# LargeDummyDevice register map
File version: 1.0
Registers are 32-bit, read-write, no defined reset value unless marked. A register's access mark holds for its fields unless they carry their own. Offsets are from the block's base; [hi:lo] are bit positions.

## PERIPHERAL_80
Base 0x4004F000
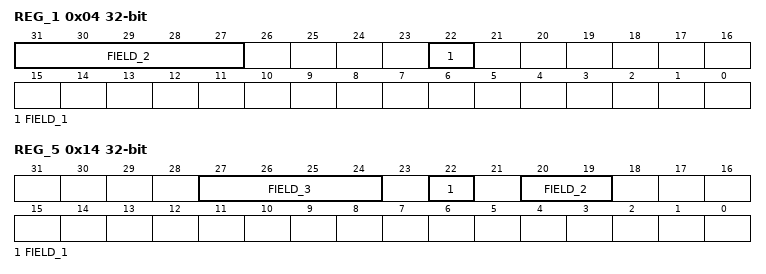
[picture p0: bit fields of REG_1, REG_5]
0x04 REG_1 — Register 1
  [31:27] FIELD_2, [22] FIELD_1
0x08 REG_2 — Register 2
  [28:25] FIELD_6, [24:21] FIELD_1, [22:20] FIELD_17, [18] FIELD_19, [16:14] FIELD_10, [11] FIELD_3, [14:10] FIELD_13, [10:9] FIELD_5, [10:9] FIELD_9, [12:9] FIELD_14, [9] FIELD_16, [6] FIELD_7, [7:5] FIELD_18, [4] FIELD_4, [5:4] FIELD_8, [6:4] FIELD_15, [5:2] FIELD_2, [5:1] FIELD_12, [4:0] FIELD_11
0x0C REG_3 — Register 3
  [24:20] FIELD_4, [23:20] FIELD_6, [17:15] FIELD_5, [8:7] FIELD_1, [8:6] FIELD_2, [1] FIELD_3
0x10 REG_4 — Register 4
  [32:28] FIELD_9, [25] FIELD_10, [25:21] FIELD_4, [18:16] FIELD_3, [14:13] FIELD_5, [16:12] FIELD_2, [12:10] FIELD_6, [10:7] FIELD_1, [6:5] FIELD_8, [5:1] FIELD_7
0x14 REG_5 — Register 5
  [27:24] FIELD_3, [22] FIELD_1, [20:19] FIELD_2
0x18 REG_6 — Register 6
  [13:12] FIELD_3, [2] FIELD_2, [4:0] FIELD_1
0x1C REG_7 — Register 7
  [35:31] FIELD_29, [34:30] FIELD_4, [31:29] FIELD_15, [29] FIELD_30, [32:29] FIELD_31, [30:28] FIELD_17, [27] FIELD_13, [29:27] FIELD_20, [25] FIELD_12, [26:23] FIELD_10, [25:23] FIELD_19, [23] FIELD_23, [22:21] FIELD_24, [22:18] FIELD_28, [16:14] FIELD_7, [17:14] FIELD_8, [14:13] FIELD_1, [13] FIELD_5, [14:12] FIELD_22, [13:11] FIELD_6, [14:10] FIELD_16, [12:8] FIELD_3, [8] FIELD_14, [10:7] FIELD_26, [8:7] FIELD_27, [6:5] FIELD_9, [7:5] FIELD_32, [6:4] FIELD_18, [4:2] FIELD_2, [2:1] FIELD_21, [2:0] FIELD_11, [2:0] FIELD_25
0x20 REG_8 — Register 8
  [28] FIELD_8, [29:27] FIELD_10, [23:22] FIELD_7, [18:14] FIELD_3, [18:14] FIELD_5, [10:7] FIELD_4, [8:7] FIELD_6, [9:5] FIELD_1, [5] FIELD_2, [7:5] FIELD_9, [4:2] FIELD_11
0x24 REG_9 — Register 9
  [31] FIELD_10, [32:31] FIELD_12, [30:29] FIELD_18, [31:27] FIELD_15, [28:27] FIELD_23, [26] FIELD_9, [24] FIELD_1, [26:24] FIELD_14, [22] FIELD_3, [21:20] FIELD_13, [23:20] FIELD_20, [22:19] FIELD_11, [21:18] FIELD_17, [17] FIELD_7, [19:16] FIELD_2, [16:14] FIELD_22, [13:12] FIELD_5, [11] FIELD_21, [10:9] FIELD_6, [6:5] FIELD_16, [5:2] FIELD_8, [4:2] FIELD_19, [5:1] FIELD_4
0x28 REG_10 — Register 10
  [33:30] FIELD_3, [29:28] FIELD_7, [24:22] FIELD_5, [12:11] FIELD_6, [12:8] FIELD_2, [11:7] FIELD_4, [7:4] FIELD_1
0x2C REG_11 — Register 11
  [32:31] FIELD_6, [31] FIELD_24, [32:30] FIELD_10, [29] FIELD_15, [31:27] FIELD_2, [26] FIELD_9, [27:25] FIELD_26, [26:23] FIELD_17, [22] FIELD_3, [24:22] FIELD_28, [23:21] FIELD_5, [24:21] FIELD_16, [23:21] FIELD_21, [17] FIELD_7, [18:15] FIELD_1, [15:14] FIELD_11, [14] FIELD_12, [18:14] FIELD_20, [14:13] FIELD_18, [11] FIELD_8, [8] FIELD_4, [11:8] FIELD_14, [11:7] FIELD_19, [7:6] FIELD_23, [9:5] FIELD_25, [3:2] FIELD_22, [4:2] FIELD_27, [1] FIELD_13
0x30 REG_12 — Register 12
  [33:31] FIELD_8, [29:28] FIELD_4, [26:22] FIELD_1, [23:21] FIELD_13, [20] FIELD_6, [18:15] FIELD_10, [15:13] FIELD_7, [11] FIELD_9, [13:9] FIELD_3, [11:8] FIELD_5, [8:7] FIELD_11, [7:6] FIELD_12, [7:4] FIELD_2, [5:1] FIELD_14
0x34 REG_13 — Register 13
  [31:30] FIELD_9, [32:30] FIELD_11, [30:28] FIELD_14, [31:27] FIELD_13, [29:25] FIELD_15, [23] FIELD_17, [27:23] FIELD_19, [24:22] FIELD_16, [22:20] FIELD_8, [20:19] FIELD_10, [20:18] FIELD_5, [19:18] FIELD_7, [20:17] FIELD_21, [17:16] FIELD_20, [15:13] FIELD_2, [10] FIELD_1, [13:10] FIELD_3, [11:10] FIELD_23, [8] FIELD_22, [6:3] FIELD_4, [4:3] FIELD_18, [1] FIELD_12, [4:0] FIELD_6
0x38 REG_14 — Register 14
  [31:30] FIELD_3, [33:30] FIELD_13, [26] FIELD_7, [22:21] FIELD_11, [20:17] FIELD_4, [19:15] FIELD_6, [16:14] FIELD_2, [14] FIELD_5, [14] FIELD_9, [10:8] FIELD_12, [11:7] FIELD_10, [6:5] FIELD_8, [6:2] FIELD_1
0x3C REG_15 — Register 15
  [34:30] FIELD_2, [32:30] FIELD_3, [33:30] FIELD_8, [30:28] FIELD_1, [27] FIELD_11, [27] FIELD_17, [27:25] FIELD_15, [26:24] FIELD_13, [19:18] FIELD_10, [11] FIELD_6, [8:6] FIELD_16, [9:5] FIELD_4, [8:5] FIELD_7, [8:5] FIELD_9, [5:4] FIELD_5, [3:1] FIELD_14, [2:0] FIELD_12
0x40 REG_16 — Register 16
  [29:27] FIELD_8, [31:27] FIELD_9, [28:25] FIELD_6, [22:18] FIELD_4, [19:16] FIELD_10, [15:13] FIELD_1, [16:13] FIELD_2, [15:13] FIELD_5, [5] FIELD_7, [7:4] FIELD_11, [4:3] FIELD_3
0x44 REG_17 — Register 17
  [34:31] FIELD_11, [32:29] FIELD_13, [31:28] FIELD_14, [27] FIELD_15, [26] FIELD_18, [24:23] FIELD_10, [22:21] FIELD_5, [24:20] FIELD_17, [23:19] FIELD_4, [22:18] FIELD_8, [20:17] FIELD_6, [18:16] FIELD_9, [14:13] FIELD_12, [12:10] FIELD_3, [5:3] FIELD_19, [5:2] FIELD_2, [4:2] FIELD_16, [3:1] FIELD_1, [1] FIELD_7
0x48 REG_18 — Register 18
  [33:30] FIELD_17, [29] FIELD_6, [29:28] FIELD_9, [28:25] FIELD_10, [27:24] FIELD_3, [25:24] FIELD_5, [26:22] FIELD_13, [19] FIELD_16, [18] FIELD_14, [20:17] FIELD_12, [15:13] FIELD_2, [14:12] FIELD_11, [14:11] FIELD_4, [13:9] FIELD_8, [10:8] FIELD_1, [8:7] FIELD_15, [9:6] FIELD_7
0x4C REG_19 — Register 19
  [32:31] FIELD_2, [33:29] FIELD_23, [29:28] FIELD_17, [30:26] FIELD_11, [27:25] FIELD_22, [23:20] FIELD_16, [23:19] FIELD_3, [20:19] FIELD_5, [19:17] FIELD_6, [19:17] FIELD_12, [16] FIELD_1, [17:16] FIELD_19, [16:13] FIELD_21, [16:12] FIELD_18, [13:9] FIELD_9, [12:8] FIELD_20, [7:6] FIELD_13, [7:6] FIELD_14, [7:6] FIELD_15, [7:5] FIELD_7, [7:3] FIELD_8, [6:2] FIELD_10, [4:1] FIELD_4
0x50 REG_20 — Register 20
  [30] FIELD_21, [34:30] FIELD_24, [32:28] FIELD_16, [30:26] FIELD_13, [24] FIELD_26, [23] FIELD_4, [23:22] FIELD_14, [21:20] FIELD_20, [21:19] FIELD_10, [18] FIELD_22, [18:16] FIELD_15, [18:14] FIELD_7, [14] FIELD_9, [14] FIELD_18, [16:13] FIELD_5, [13:11] FIELD_19, [10:9] FIELD_25, [10:8] FIELD_1, [11:8] FIELD_12, [9:7] FIELD_3, [6] FIELD_23, [3:2] FIELD_17, [3:1] FIELD_2, [5:1] FIELD_6, [1] FIELD_11, [3:0] FIELD_8
0x54 REG_21 — Register 21
  [33:31] FIELD_27, [30:29] FIELD_4, [29:27] FIELD_7, [29:27] FIELD_15, [29:27] FIELD_24, [27:23] FIELD_1, [23:22] FIELD_2, [23:22] FIELD_9, [20] FIELD_28, [20:19] FIELD_3, [22:18] FIELD_5, [22:18] FIELD_26, [21:17] FIELD_11, [20:17] FIELD_18, [15] FIELD_21, [17:13] FIELD_30, [13:12] FIELD_29, [14:11] FIELD_23, [13:10] FIELD_13, [10] FIELD_19, [13:9] FIELD_10, [9] FIELD_22, [11:7] FIELD_6, [10:6] FIELD_16, [5] FIELD_12, [8:5] FIELD_20, [8:4] FIELD_8, [6:2] FIELD_14, [2:1] FIELD_17, [0] FIELD_25
0x58 REG_22 — Register 22
  [35:31] FIELD_6, [31:29] FIELD_4, [29:27] FIELD_13, [23] FIELD_9, [23] FIELD_12, [23:21] FIELD_11, [21:20] FIELD_14, [24:20] FIELD_17, [20:19] FIELD_2, [19] FIELD_7, [20:18] FIELD_1, [19:18] FIELD_8, [17:15] FIELD_18, [17:14] FIELD_16, [13:12] FIELD_15, [11:8] FIELD_10, [9:7] FIELD_5, [6:2] FIELD_3
0x5C REG_23 — Register 23
  [33:30] FIELD_6, [32:28] FIELD_2, [30:27] FIELD_10, [28:25] FIELD_3, [22:19] FIELD_11, [17:15] FIELD_5, [17:13] FIELD_7, [10:9] FIELD_4, [9:8] FIELD_8, [12:8] FIELD_12, [2] FIELD_9, [3:1] FIELD_13, [3:0] FIELD_1
0x60 REG_24 — Register 24
  [35:31] FIELD_5, [33:29] FIELD_16, [29:28] FIELD_11, [29:27] FIELD_13, [22:19] FIELD_7, [22:18] FIELD_10, [18:15] FIELD_1, [18:15] FIELD_2, [17:15] FIELD_15, [16:13] FIELD_12, [15:12] FIELD_14, [8:7] FIELD_9, [6:5] FIELD_8, [1] FIELD_6, [1:0] FIELD_3, [0] FIELD_4
0x64 REG_25 — Register 25
  [31:30] FIELD_21, [32:30] FIELD_22, [29:27] FIELD_3, [27] FIELD_5, [27] FIELD_17, [28:26] FIELD_10, [25:23] FIELD_7, [22] FIELD_23, [22:20] FIELD_2, [23:20] FIELD_14, [19:16] FIELD_6, [18:16] FIELD_8, [15] FIELD_19, [14:13] FIELD_20, [16:12] FIELD_11, [13:12] FIELD_18, [9] FIELD_12, [7:4] FIELD_1, [8:4] FIELD_13, [5:3] FIELD_4, [2:0] FIELD_9, [3:0] FIELD_15, [4:0] FIELD_16
0x68 REG_26 — Register 26
  [32:30] FIELD_5, [30:29] FIELD_19, [31:28] FIELD_20, [30:26] FIELD_6, [25] FIELD_25, [26:25] FIELD_26, [25:24] FIELD_9, [27:23] FIELD_24, [25:21] FIELD_13, [22:21] FIELD_16, [24:20] FIELD_23, [19] FIELD_7, [19:17] FIELD_10, [18:17] FIELD_27, [20:16] FIELD_14, [14] FIELD_1, [16:14] FIELD_4, [16:14] FIELD_18, [13] FIELD_17, [12:11] FIELD_8, [12:9] FIELD_22, [9:7] FIELD_3, [4:2] FIELD_11, [6:2] FIELD_21, [1:0] FIELD_2, [4:0] FIELD_12, [0] FIELD_15
